# AT32F402xx_v2 register map
Vendor: Keil; Series: AT32F402; File version: 1.0
CPU: CM4 r0p1, little endian, no MPU, FPU, 4 interrupt priority bits
Registers are 32-bit, read-write, reset 0x0 unless marked. A register's access mark holds for its fields unless they carry their own. Offsets are from the block's base; [hi:lo] are bit positions; {n}, {i} and the like mark numbered series; 'fields as' and 'values as' point back to an identical list.

## USB_OTGHS_DEVICE — USB on the go high speed
Base 0x40040800
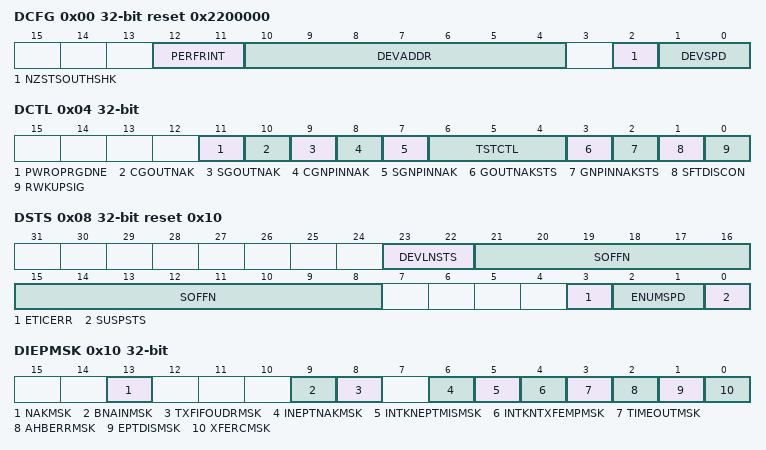
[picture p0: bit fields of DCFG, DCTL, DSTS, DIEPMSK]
0x00 DCFG reset 0x2200000 — OTGHS device configuration register (OTGHS_DCFG)
  [12:11] PERFRINT — Periodic frame interval
  [10:4] DEVADDR — Device address
  [2] NZSTSOUTHSHK — Non-zero-length status OUT handshake
  [1:0] DEVSPD — Device speed
0x04 DCTL — OTGHS device control register (OTGHS_DCTL)
  [11] PWROPRGDNE — Power-on programming done
  [10] CGOUTNAK — Clear global OUT NAK
  [9] SGOUTNAK — Set global OUT NAK
  [8] CGNPINNAK — Clear global IN NAK
  [7] SGNPINNAK — Set global IN NAK
  [6:4] TSTCTL — Test control
  [3] GOUTNAKSTS ro — Global OUT NAK status
  [2] GNPINNAKSTS ro — Global IN NAK status
  [1] SFTDISCON — Soft disconnect
  [0] RWKUPSIG — Remote wakeup signaling
0x08 DSTS ro reset 0x10 — OTGFS device status register (OTGFS_DSTS)
  [23:22] DEVLNSTS — Device Line Status
  [21:8] SOFFN — Frame number of the received SOF
  [3] ETICERR — Erratic error
  [2:1] ENUMSPD — Enumerated speed
  [0] SUSPSTS — Suspend status
0x10 DIEPMSK — OTGHS device IN endpoint common interrupt mask register (OTGHS_DIEPMSK)
  [13] NAKMSK — NAK interrupt mask
  [9] BNAINMSK — BNA interrupt mask
  [8] TXFIFOUDRMSK — FIFO underrun mask
  [6] INEPTNAKMSK — IN endpoint NAK effective mask
  [5] INTKNEPTMISMSK — IN token received with EP mismatch mask
  [4] INTKNTXFEMPMSK — IN token received when TxFIFO empty mask
  [3] TIMEOUTMSK — Timeout condition mask (Non-isochronous endpoints)
  [2] AHBERRMSK — AHB Error mask
  [1] EPTDISMSK — Endpoint disabled interrupt mask
  [0] XFERCMSK — Transfer completed interrupt mask
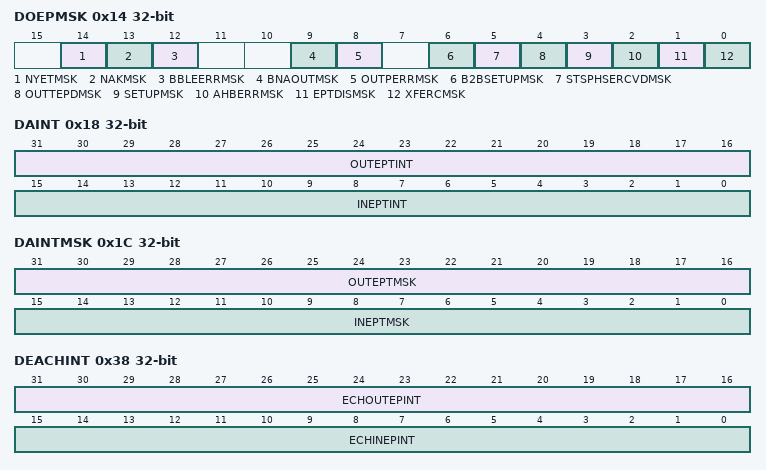
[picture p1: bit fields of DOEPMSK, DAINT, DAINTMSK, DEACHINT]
0x14 DOEPMSK — OTGHS device OUT endpoint common interrupt mask register (OTGHS_DOEPMSK)
  [14] NYETMSK — NYET interrupt mask
  [13] NAKMSK — NAK interrupt mask
  [12] BBLEERRMSK — Babble Error interrupt mask
  [9] BNAOUTMSK — BNA interrupt mask
  [8] OUTPERRMSK — OUT packet error mask
  [6] B2BSETUPMSK — Back-to-back SETUP packets received mask
  [5] STSPHSERCVDMSK — Status Phase Received mask
  [4] OUTTEPDMSK — OUT token received when endpoint disabled mask
  [3] SETUPMSK — SETUP phase done mask
  [2] AHBERRMSK — AHB Error mask
  [1] EPTDISMSK — Endpoint disabled interrupt mask
  [0] XFERCMSK — Transfer completed interrupt mask
0x18 DAINT ro — OTGHS device all endpoints interrupt register (OTGHS_DAINT)
  [31:16] OUTEPTINT — OUT endpoint interrupt bits
  [15:0] INEPTINT — IN endpoint interrupt bits
0x1C DAINTMSK — OTGHS all endpoints interrupt mask register (OTGHS_DAINTMSK)
  [31:16] OUTEPTMSK — OUT endpoint interrupt bits
  [15:0] INEPTMSK — IN EP interrupt mask bits
0x34 DIEPEMPMSK — OTGHS device IN endpoint FIFO empty interrupt mask register
  [15:0] INEPTXFEMSK — IN EP Tx FIFO empty interrupt mask bits
0x38 DEACHINT — ODevice Each Endpoints Interrupt Register
  [31:16] ECHOUTEPINT — Each OUT Endpoint Interrupt bits
  [15:0] ECHINEPINT — Each IN Endpoint Interrupt bits
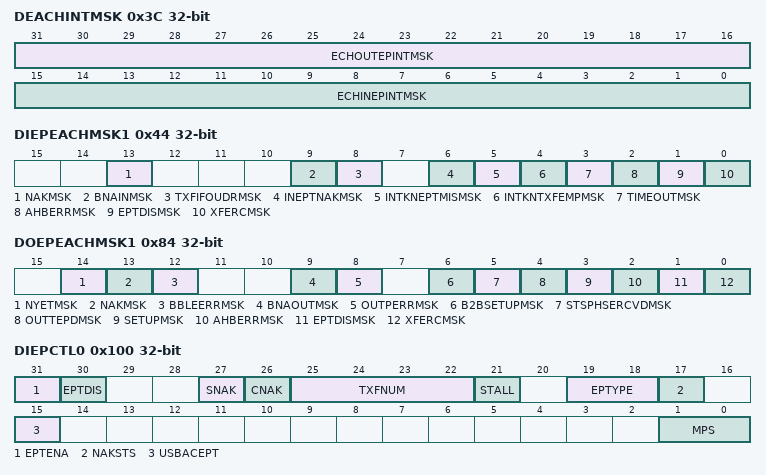
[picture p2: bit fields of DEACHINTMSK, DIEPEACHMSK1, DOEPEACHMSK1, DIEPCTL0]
0x3C DEACHINTMSK — Device Each Endpoints Interrupt Mask Register
  [31:16] ECHOUTEPINTMSK — Each OUT Endpoint Interrupt Mask bits
  [15:0] ECHINEPINTMSK — Each IN Endpoint Interrupt Mask bits
0x44 DIEPEACHMSK1 — Device Each IN Endpoint 1 Interrupt Register
  fields as DIEPMSK
0x84 DOEPEACHMSK1 — Device Each OUT Endpoint 1 Interrupt Register
  fields as DOEPMSK
0x100 DIEPCTL0 — OTGHS device control IN endpoint 0 control register (OTGHS_DIEPCTL0)
  [31] EPTENA — Endpoint enable
  [30] EPTDIS — Endpoint disable
  [27] SNAK wo — Set NAK
  [26] CNAK wo — Clear NAK
  [25:22] TXFNUM — TxFIFO number
  [21] STALL — STALL handshake
  [19:18] EPTYPE ro — Endpoint type
  [17] NAKSTS ro — NAK status
  [15] USBACEPT ro — USB active endpoint
  [1:0] MPS — Maximum packet size
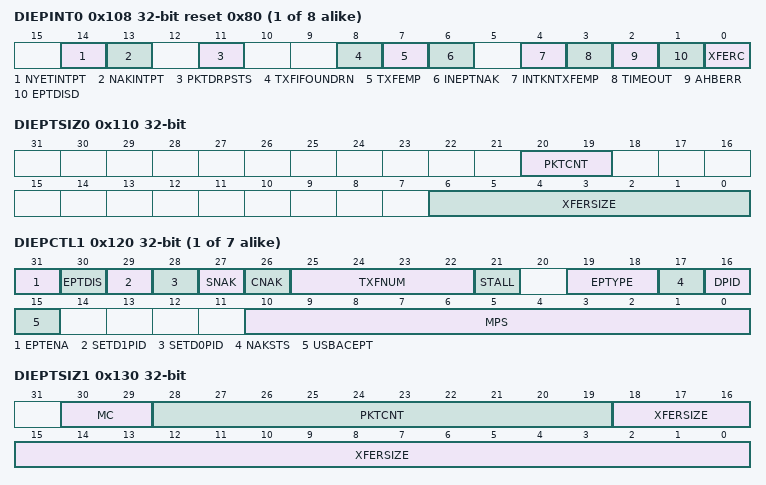
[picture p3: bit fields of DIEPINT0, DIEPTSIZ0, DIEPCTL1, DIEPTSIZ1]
{0x108+0x20*i} DIEPINT{i} reset 0x80 (i=0..7) — OTGHS device IN endpoint-{i} interrupt register
  [14] NYETINTPT — NYET interrupt
  [13] NAKINTPT — NAK interrupt
  [11] PKTDRPSTS — Packet Drop Status
  [8] TXFIFOUNDRN — Fifo Underrun
  [7] TXFEMP ro — Transmit FIFO empty
  [6] INEPTNAK — IN endpoint NAK effective
  [4] INTKNTXFEMP — IN token received when TxFIFO is empty
  [3] TIMEOUT — Timeout condition
  [2] AHBERR — AHB Error interrupt
  [1] EPTDISD — Endpoint disabled interrupt
  [0] XFERC — Transfer completed interrupt
0x110 DIEPTSIZ0 — OTGHS device IN endpoint-0 transfer size register
  [20:19] PKTCNT — Packet count
  [6:0] XFERSIZE — Transfer size
{0x114+0x20*i} DIEPDMA{i} (i=0..7) — Device IN Endpoint {i} DMA Address register
  [31:0] DMAADDR — DMA Address
{0x118+0x20*i} DTXFSTS{i} ro (i=0..7) — OTGHS device IN endpoint-{i} transmit FIFO status register
  [15:0] INEPTXFSAV — IN endpoint TxFIFO space available
{0x100+0x20*i} DIEPCTL{i} (i=1..7) — OTGHS device IN endpoint-{i} control register
  [31] EPTENA — Endpoint enable
  [30] EPTDIS — Endpoint disable
  [29] SETD1PID wo — Set DATA1 PID
  [28] SETD0PID wo — Set DATA0 PID
  [27] SNAK wo — Set NAK
  [26] CNAK wo — Clear NAK
  [25:22] TXFNUM — TxFIFO number
  [21] STALL — STALL handshake
  [19:18] EPTYPE — Endpoint type
  [17] NAKSTS ro — NAK status
  [16] DPID ro — Endpoint Data PID
  [15] USBACEPT — USB active endpoint
  [10:0] MPS — Maximum packet size
0x130 DIEPTSIZ1 — OTGHS device IN endpoint-1 transfer size register
  [30:29] MC — Multi count
  [28:19] PKTCNT — Packet count
  [18:0] XFERSIZE — Transfer size
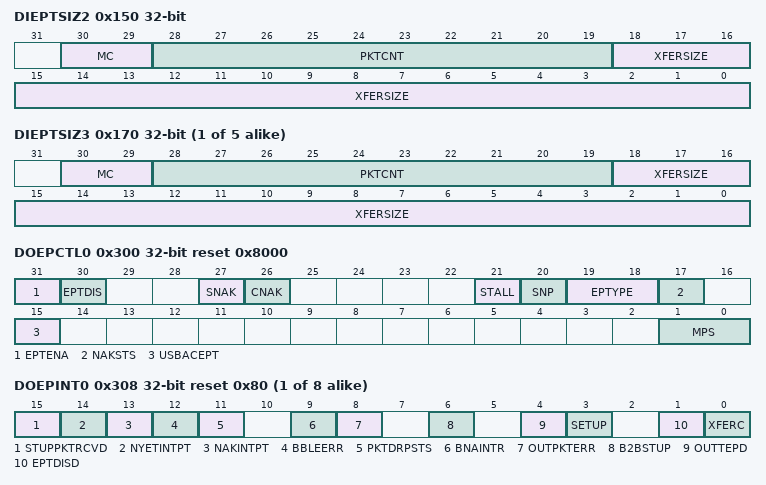
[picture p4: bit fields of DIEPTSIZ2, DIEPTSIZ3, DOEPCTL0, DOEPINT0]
0x150 DIEPTSIZ2 — OTGHS device IN endpoint-2 transfer size register
  fields as DIEPTSIZ1
{0x110+0x20*i} DIEPTSIZ{i} (i=3..7) — OTG device IN endpoint-{i} transfer size register
  fields as DIEPTSIZ1
0x300 DOEPCTL0 reset 0x8000 — OTGHS device OUT endpoint-0 control register
  [31] EPTENA — Endpoint enable
  [30] EPTDIS — Endpoint disable
  [27] SNAK wo — Set NAK
  [26] CNAK wo — Clear NAK
  [21] STALL — STALL handshake
  [20] SNP — Snoop mode
  [19:18] EPTYPE ro — Endpoint type
  [17] NAKSTS ro — NAK status
  [15] USBACEPT ro — USB active endpoint
  [1:0] MPS ro — Maximum packet size
{0x308+0x20*i} DOEPINT{i} reset 0x80 (i=0..7) — OTGHS device OUT endpoint-{i} interrupt register
  [15] STUPPKTRCVD — Setup Packet Received
  [14] NYETINTPT — NYET interrupt
  [13] NAKINTPT — NAK interrupt
  [12] BBLEERR — BBLE error
  [11] PKTDRPSTS — Packet Drop Status
  [9] BNAINTR — Buffer Not Available Error
  [8] OUTPKTERR — OUT Packet Error
  [6] B2BSTUP — Back-to-back SETUP packets received
  [4] OUTTEPD — OUT token received when endpoint disabled
  [3] SETUP — SETUP phase done
  [1] EPTDISD — Endpoint disabled interrupt
  [0] XFERC — Transfer completed interrupt
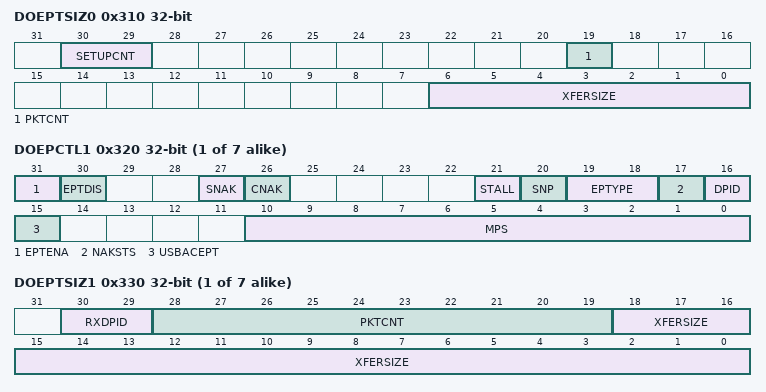
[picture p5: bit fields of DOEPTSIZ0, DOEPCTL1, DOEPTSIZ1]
0x310 DOEPTSIZ0 — OTGHS device OUT endpoint-0 transfer size register
  [30:29] SETUPCNT — SETUP packet count
  [19] PKTCNT — Packet count
  [6:0] XFERSIZE — Transfer size
{0x314+0x20*i} DOEPDMA{i} (i=0..7) — Device OUT Endpoint {i} DMA Address register
  [31:0] DMAADDR — DMA Address
{0x300+0x20*i} DOEPCTL{i} (i=1..7) — OTGHS device OUT endpoint-{i} control register
  [31] EPTENA — Endpoint enable
  [30] EPTDIS — Endpoint disable
  [27] SNAK wo — Set NAK
  [26] CNAK wo — Clear NAK
  [21] STALL — STALL handshake
  [20] SNP — Snoop mode
  [19:18] EPTYPE — Endpoint type
  [17] NAKSTS ro — NAK status
  [16] DPID ro — Endpoint data PID
  [15] USBACEPT — USB active endpoint
  [10:0] MPS — Maximum packet size
{0x310+0x20*i} DOEPTSIZ{i} (i=1..7) — OTGHS device OUT endpoint-{i} transfer size register
  [30:29] RXDPID — Received data PID
  [28:19] PKTCNT — Packet count
  [18:0] XFERSIZE — Transfer size
